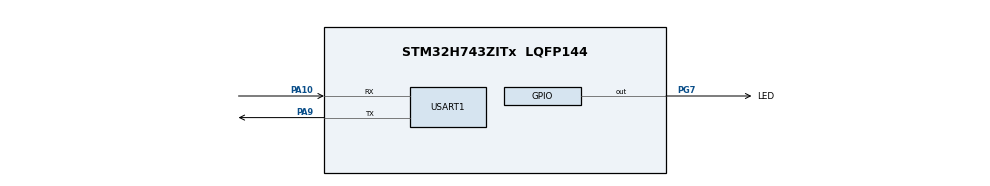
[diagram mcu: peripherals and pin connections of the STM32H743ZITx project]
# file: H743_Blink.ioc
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CORTEX_M7.CPU_DCache=Disabled
CORTEX_M7.CPU_ICache=Disabled
Mcu.Family=STM32H7
Mcu.Name=STM32H743ZITx
Mcu.Package=LQFP144
NVIC.PriorityGroup=NVIC_PRIORITYGROUP_4
NVIC.USART1_IRQn=true\:0\:0\:false\:false\:true\:true\:true
PA10.Mode=Asynchronous
PA10.Signal=USART1_RX
PA13\ (JTMS/SWDIO).Mode=Trace_Synchro_4bits_JTAG
PA13\ (JTMS/SWDIO).Signal=DEBUG_JTMS-SWDIO
PA14\ (JTCK/SWCLK).Mode=Trace_Synchro_4bits_JTAG
PA14\ (JTCK/SWCLK).Signal=DEBUG_JTCK-SWCLK
PA15\ (JTDI).Mode=Trace_Synchro_4bits_JTAG
PA15\ (JTDI).Signal=DEBUG_JTDI
PA9.Mode=Asynchronous
PA9.Signal=USART1_TX
PB3\ (JTDO/TRACESWO).Mode=Trace_Synchro_4bits_JTAG
PB3\ (JTDO/TRACESWO).Signal=DEBUG_JTDO-SWO
PE2.Mode=Trace_Synchro_4bits_JTAG
PE2.Signal=DEBUG_TRACECLK
PE3.Mode=Trace_Synchro_4bits_JTAG
PE3.Signal=DEBUG_TRACED0
PE4.Mode=Trace_Synchro_4bits_JTAG
PE4.Signal=DEBUG_TRACED1
PE5.Mode=Trace_Synchro_4bits_JTAG
PE5.Signal=DEBUG_TRACED2
PE6.Mode=Trace_Synchro_4bits_JTAG
PE6.Signal=DEBUG_TRACED3
PG7.GPIO_Label=LED
PG7.GPIO_Speed=GPIO_SPEED_FREQ_VERY_HIGH
PG7.PinState=GPIO_PIN_RESET
PG7.Signal=GPIO_Output
PH0-OSC_IN\ (PH0).Mode=HSE-External-Oscillator
PH0-OSC_IN\ (PH0).Signal=RCC_OSC_IN
PH1-OSC_OUT\ (PH1).Mode=HSE-External-Oscillator
PH1-OSC_OUT\ (PH1).Signal=RCC_OSC_OUT
ProjectManager.HeapSize=0x200
ProjectManager.StackSize=0x400
ProjectManager.TargetToolchain=Makefile
RCC.ADCFreq_Value=50000000
RCC.APB1Freq_Value=100000000
RCC.APB2Freq_Value=100000000
RCC.APB3Freq_Value=100000000
RCC.APB4Freq_Value=100000000
RCC.CortexFreq_Value=200000000
RCC.DIVM1=2
RCC.DIVM3=16
RCC.DIVN1=32
RCC.DIVN2=128
RCC.DIVN3=128
RCC.DIVQ3=4
RCC.DIVR1=4
RCC.HCLKFreq_Value=100000000
RCC.HPRE=RCC_HCLK_DIV2
RCC.PLLSourceVirtual=RCC_PLLSOURCE_HSE
RCC.SYSCLKFreq_VALUE=200000000
RCC.SYSCLKSource=RCC_SYSCLKSOURCE_PLLCLK
RCC.USART16CLockSelection=RCC_USART16CLKSOURCE_PLL3
RCC.USBFreq_Value=200000000
USART1.VirtualMode-Asynchronous=VM_ASYNC
board=custom

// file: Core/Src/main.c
/* USER CODE BEGIN Header */
/**
  ******************************************************************************
  * @file           : main.c
  * @brief          : Main program body
  ******************************************************************************
  * @attention
  *
  * Copyright (c) 2026 STMicroelectronics.
  * All rights reserved.
  *
  * This software is licensed under terms that can be found in the LICENSE file
  * in the root directory of this software component.
  * If no LICENSE file comes with this software, it is provided AS-IS.
  *
  ******************************************************************************
  */
/* USER CODE END Header */
#include "main.h"

/* USER CODE BEGIN Includes */
#include "coremark_port.h"
/* USER CODE END Includes */

/* USER CODE BEGIN PD */
/* PLL dividers used to live here (dead defines, board_clock.c owns the real
 * cold-init values; runtime changes go via the UART CLI `pll --apply`). */
/* USER CODE END PD */

UART_HandleTypeDef huart1;

void SystemClock_Config(void);
static void MX_GPIO_Init(void);
static void MX_USART1_UART_Init(void);

/* USER CODE BEGIN 0 */
/* func_test: a call-graph workload for ETM trace bring-up. Every function is
 * kept as a real BL/BLX (build with -O0 and marked noinline) so branch
 * broadcast produces a dense, decodable stream. NB: with -Og/-O2 the leaf
 * helpers get inlined away, which starves the decoder of branch anchors --
 * that is why the high-TRACECLK capture looked mostly like HSYNC filler. */

#define NOINLINE __attribute__((noinline))

static volatile uint32_t sink;       /* defeat dead-code elimination */
static volatile uint32_t isr_count;  /* interrupt counter */

/* ---- leaf functions (return via BX LR, no stack frame) ---- */

static NOINLINE uint32_t leaf_add(uint32_t a, uint32_t b) {
    return a + b;  /* BX LR */
}

static NOINLINE uint32_t leaf_mul(uint32_t a, uint32_t b) {
    return a * b;  /* BX LR */
}

/* ---- callback invoked from a periodic timer ISR ---- */

void timer_isr_callback(void) {
    /* a light but branchy ISR: nested call + conditional branch */
    isr_count++;
    if (isr_count & 1) {
        sink += leaf_add(isr_count, 3);
    } else {
        sink += leaf_mul(isr_count, 2);
    }
}

/* ---- frame function (returns via POP {PC}, has a stack frame) ---- */

static NOINLINE uint32_t frame_func(uint32_t a, uint32_t b, uint32_t c) {
    volatile uint32_t local = a * b + c;
    return local + leaf_add(a, c);  /* nested leaf call */
}

/* ---- direct call chain A -> B -> C ---- */

static NOINLINE uint32_t level_c(uint32_t x) {
    return leaf_mul(x, 2);
}

static NOINLINE uint32_t level_b(uint32_t x) {
    return level_c(x + 1) + leaf_add(x, 1);
}

static NOINLINE uint32_t level_a(uint32_t x) {
    return level_b(x + 1) + frame_func(x, 2, 3);
}

/* ---- indirect calls through a function pointer (BLX) ---- */

typedef uint32_t (*op_fn)(uint32_t, uint32_t);

static NOINLINE uint32_t op_add(uint32_t a, uint32_t b) { return a + b; }
static NOINLINE uint32_t op_sub(uint32_t a, uint32_t b) { return a - b; }
static NOINLINE uint32_t op_mul(uint32_t a, uint32_t b) { return a * b; }

static const op_fn op_table[3] = { op_add, op_sub, op_mul };

static NOINLINE uint32_t indirect_caller(uint32_t idx, uint32_t a, uint32_t b) {
    op_fn fn = op_table[idx % 3];  /* function pointer table lookup */
    return fn(a, b);  /* BLX indirect call */
}

/* ---- callback pattern (models an LVGL-style event callback) ---- */

typedef void (*callback_t)(uint32_t);

static NOINLINE void cb_handler_a(uint32_t arg) {
    sink += arg;
}

static NOINLINE void cb_handler_b(uint32_t arg) {
    sink += arg * 2;
}

static NOINLINE void dispatch_callback(callback_t cb, uint32_t arg) {
    cb(arg);  /* BLX indirect call to the callback */
}

static NOINLINE void callback_test(void) {
    dispatch_callback(cb_handler_a, 1);
    dispatch_callback(cb_handler_b, 2);
    dispatch_callback(cb_handler_a, 3);
}

/* ---- recursion ---- */

static NOINLINE uint32_t factorial(uint32_t n) {
    if (n <= 1) {
        return 1;
    }
    return n * factorial(n - 1);  /* recursive call */
}

/* ---- deep nesting (6 levels) ---- */

static NOINLINE void deep6(void) {  sink++; }
static NOINLINE void deep5(void) {  deep6(); }
static NOINLINE void deep4(void) {  deep5(); }
static NOINLINE void deep3(void) {  deep4(); }
static NOINLINE void deep2(void) {  deep3(); }
static NOINLINE void deep1(void) {  deep2(); }

/* ---- repeated calls to the same function (checks stack balance) ---- */

static NOINLINE uint32_t pingpong(uint32_t n) {
    return leaf_add(n, 1);
}

static NOINLINE void repeat_test(void) {
    for (int i = 0; i < 5; i++) {
        pingpong(i);  /* same target 5x -> a B/E atom each time */
    }
}

/* ---- conditional branch (checks B / !B atom decoding) ---- */

static NOINLINE uint32_t conditional(uint32_t x) {
    if (x & 1) {
        return leaf_add(x, 10);
    } else {
        return leaf_mul(x, 10);
    }
}

/* ---- mixed: direct + indirect + recursion + callback ---- */

static NOINLINE uint32_t mixed_test(uint32_t x) {
    uint32_t r1 = level_a(x);               /* direct call chain */
    uint32_t r2 = indirect_caller(x, 3, 4); /* indirect call */
    uint32_t r3 = factorial(3);             /* recursion */
    return r1 + r2 + r3;
}

/* ---- main loop (tight, no delay, high trace density) ----
 * REPS batches the whole test suite so each capture window sees many
 * iterations back-to-back, keeping the parallel trace port fed even at high
 * TRACECLK (avoids the HSYNC-filler / anchor-starvation regime).
 *
 * REPS is large and the hot loop has NO HAL_GetTick()/LED polling: at high
 * TRACECLK the ETF (4KB) drains faster than a light workload emits trace, so
 * the TPIU pads with full-sync frames that shred ETM frame phase. A dense,
 * uninterrupted branch stream keeps the ETF fed so real ETM dominates the
 * port instead of sync filler. The heartbeat was removed from the hot path
 * because HAL_GetTick polling injects idle gaps + pulls HAL code into trace. */
#define REPS 200

void main_loop(void) {
    volatile uint32_t acc = 0;
    while (1) {
        for (int r = 0; r < REPS; r++) {
            /* Test 1: direct call chain */
            acc += level_a(r);

            /* Test 2: indirect calls (all 3 operators) */
            acc += indirect_caller(0, r, 20);
            acc += indirect_caller(1, r, 20);
            acc += indirect_caller(2, r, 20);

            /* Test 3: callback pattern */
            callback_test();

            /* Test 4: recursion (varying depth for more branches) */
            acc += factorial(1 + (r & 7));

            /* Test 5: deep nesting */
            deep1();

            /* Test 6: repeated calls */
            repeat_test();

            /* Test 7: conditional branches (both arms, data-dependent) */
            acc += conditional(r);
            acc += conditional(r + 1);

            /* Test 8: mixed */
            acc += mixed_test(r & 3);
        }
        sink = acc;   /* keep acc live so nothing is optimised out */
    }
}
/* USER CODE END 0 */

int main(void)
{

  /* MCU Configuration--------------------------------------------------------*/

  /* Reset of all peripherals, Initializes the Flash interface and the Systick. */
  HAL_Init();

  /* Configure the system clock */
  SystemClock_Config();

  /* Initialize all configured peripherals */
  MX_GPIO_Init();
  MX_USART1_UART_Init();
  /* USER CODE BEGIN 2 */
  /* Boot order:
   *   board_clock_override() -> cold-init PLL to sysclk 150M / pll1_r_ck 225M
   *   cm_uart_init(&huart1)  -> shared USART1 handle for printf/CLI/ee_printf
   *   cli_init(&huart1)      -> arm the argparse-based UART command line
   * After this main() falls into the CLI-driven scheduler in the WHILE loop
   * (see workload_run() in cli.c). The workload (selftrace / coremark / idle)
   * is chosen at runtime via the `run` command -- no compile switch. */
  board_clock_override();
  cm_uart_init(&huart1);
  extern void cli_init(UART_HandleTypeDef *huart);
  cli_init(&huart1);
  /* USER CODE END 2 */

  /* Infinite loop */
  /* USER CODE BEGIN WHILE */
  {
    extern void workload_run(void);
    workload_run();  /* never returns; polls CLI + runs the selected task */
  }
  while (1) { }
    /* USER CODE END WHILE */

}

void SystemClock_Config(void)
{
  RCC_OscInitTypeDef RCC_OscInitStruct = {0};
  RCC_ClkInitTypeDef RCC_ClkInitStruct = {0};

  /** Supply configuration update enable
  */
  HAL_PWREx_ConfigSupply(PWR_LDO_SUPPLY);
  /** Configure the main internal regulator output voltage
  */
  __HAL_PWR_VOLTAGESCALING_CONFIG(PWR_REGULATOR_VOLTAGE_SCALE3);

  while(!__HAL_PWR_GET_FLAG(PWR_FLAG_VOSRDY)) {}
  /** Macro to configure the PLL clock source
  */
  __HAL_RCC_PLL_PLLSOURCE_CONFIG(RCC_PLLSOURCE_HSE);
  /** Initializes the RCC Oscillators according to the specified parameters
  * in the RCC_OscInitTypeDef structure.
  */
  RCC_OscInitStruct.OscillatorType = RCC_OSCILLATORTYPE_HSE;
  RCC_OscInitStruct.HSEState = RCC_HSE_ON;
  RCC_OscInitStruct.PLL.PLLState = RCC_PLL_ON;
  RCC_OscInitStruct.PLL.PLLSource = RCC_PLLSOURCE_HSE;
  RCC_OscInitStruct.PLL.PLLM = 2;
  RCC_OscInitStruct.PLL.PLLN = 32;
  RCC_OscInitStruct.PLL.PLLP = 2;
  RCC_OscInitStruct.PLL.PLLQ = 2;
  RCC_OscInitStruct.PLL.PLLR = 4;
  RCC_OscInitStruct.PLL.PLLRGE = RCC_PLL1VCIRANGE_3;
  RCC_OscInitStruct.PLL.PLLVCOSEL = RCC_PLL1VCOWIDE;
  RCC_OscInitStruct.PLL.PLLFRACN = 0;
  if (HAL_RCC_OscConfig(&RCC_OscInitStruct) != HAL_OK)
  {
    Error_Handler();
  }
  /** Initializes the CPU, AHB and APB buses clocks
  */
  RCC_ClkInitStruct.ClockType = RCC_CLOCKTYPE_HCLK|RCC_CLOCKTYPE_SYSCLK
                              |RCC_CLOCKTYPE_PCLK1|RCC_CLOCKTYPE_PCLK2
                              |RCC_CLOCKTYPE_D3PCLK1|RCC_CLOCKTYPE_D1PCLK1;
  RCC_ClkInitStruct.SYSCLKSource = RCC_SYSCLKSOURCE_PLLCLK;
  RCC_ClkInitStruct.SYSCLKDivider = RCC_SYSCLK_DIV1;
  RCC_ClkInitStruct.AHBCLKDivider = RCC_HCLK_DIV2;
  RCC_ClkInitStruct.APB3CLKDivider = RCC_APB3_DIV1;
  RCC_ClkInitStruct.APB1CLKDivider = RCC_APB1_DIV1;
  RCC_ClkInitStruct.APB2CLKDivider = RCC_APB2_DIV1;
  RCC_ClkInitStruct.APB4CLKDivider = RCC_APB4_DIV1;

  if (HAL_RCC_ClockConfig(&RCC_ClkInitStruct, FLASH_LATENCY_2) != HAL_OK)
  {
    Error_Handler();
  }
}

static void MX_USART1_UART_Init(void)
{

  huart1.Instance = USART1;
  huart1.Init.BaudRate = 115200;
  huart1.Init.WordLength = UART_WORDLENGTH_8B;
  huart1.Init.StopBits = UART_STOPBITS_1;
  huart1.Init.Parity = UART_PARITY_NONE;
  huart1.Init.Mode = UART_MODE_TX_RX;
  huart1.Init.HwFlowCtl = UART_HWCONTROL_NONE;
  huart1.Init.OverSampling = UART_OVERSAMPLING_16;
  huart1.Init.OneBitSampling = UART_ONE_BIT_SAMPLE_DISABLE;
  huart1.Init.ClockPrescaler = UART_PRESCALER_DIV1;
  huart1.AdvancedInit.AdvFeatureInit = UART_ADVFEATURE_NO_INIT;
  if (HAL_UART_Init(&huart1) != HAL_OK)
  {
    Error_Handler();
  }
  if (HAL_UARTEx_SetTxFifoThreshold(&huart1, UART_TXFIFO_THRESHOLD_1_8) != HAL_OK)
  {
    Error_Handler();
  }
  if (HAL_UARTEx_SetRxFifoThreshold(&huart1, UART_RXFIFO_THRESHOLD_1_8) != HAL_OK)
  {
    Error_Handler();
  }
  if (HAL_UARTEx_DisableFifoMode(&huart1) != HAL_OK)
  {
    Error_Handler();
  }

}

static void MX_GPIO_Init(void)
{
  GPIO_InitTypeDef GPIO_InitStruct = {0};

  /* GPIO Ports Clock Enable */
  __HAL_RCC_GPIOE_CLK_ENABLE();
  __HAL_RCC_GPIOH_CLK_ENABLE();
  __HAL_RCC_GPIOG_CLK_ENABLE();
  __HAL_RCC_GPIOA_CLK_ENABLE();
  __HAL_RCC_GPIOB_CLK_ENABLE();

  /*Configure GPIO pin Output Level */
  HAL_GPIO_WritePin(LED_GPIO_Port, LED_Pin, GPIO_PIN_RESET);

  /*Configure GPIO pin : LED_Pin */
  GPIO_InitStruct.Pin = LED_Pin;
  GPIO_InitStruct.Mode = GPIO_MODE_OUTPUT_PP;
  GPIO_InitStruct.Pull = GPIO_NOPULL;
  GPIO_InitStruct.Speed = GPIO_SPEED_FREQ_VERY_HIGH;
  HAL_GPIO_Init(LED_GPIO_Port, &GPIO_InitStruct);

}

void Error_Handler(void)
{
  __disable_irq();
  while (1)
  {
  }
}
